# STM32F031C4T6 register map
File version: 1.0
Registers are 32-bit, access not given, reset 0x0 unless marked. A register's access mark holds for its fields unless they carry their own. Offsets are from the block's base; [hi:lo] are bit positions; {n}, {i} and the like mark numbered series.

## TIM1
Base 0x40012C00
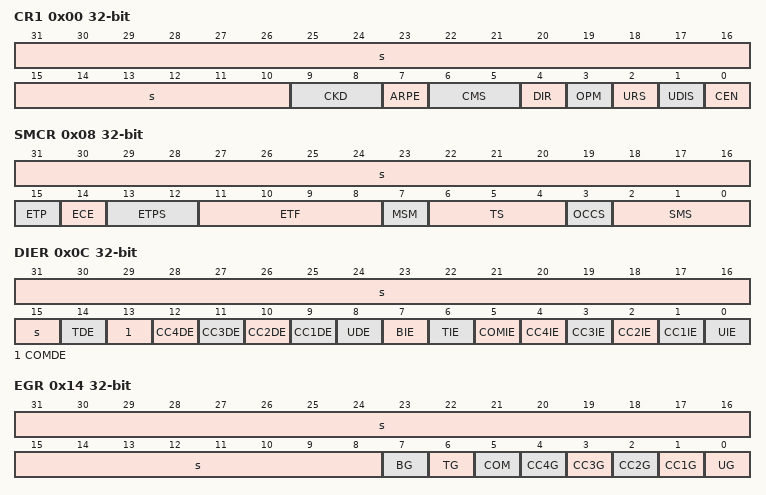
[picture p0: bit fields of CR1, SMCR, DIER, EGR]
0x00 CR1
  [31:10] s, [9:8] CKD, [7] ARPE, [6:5] CMS, [4] DIR, [3] OPM, [2] URS, [1] UDIS, [0] CEN
0x04 CR2
  [2n+6] OIS{n} (n=1..4), [13] OIS3N, [11] OIS2N, [9] OIS1N, [7] TI1S, [6:4] MMS, [3] CCDS, [2] CCUS, [31:1] s, [0] CCPC
0x08 SMCR
  [31:16] s, [15] ETP, [14] ECE, [13:12] ETPS, [11:8] ETF, [7] MSM, [6:4] TS, [3] OCCS, [2:0] SMS
0x0C DIER
  [31:15] s, [14] TDE, [13] COMDE, [n+8] CC{n}DE (n=1..4), [8] UDE, [7] BIE, [6] TIE, [5] COMIE, [n] CC{n}IE (n=1..4), [0] UIE
0x10 SR
  [n+8] CC{n}OF (n=1..4), [31:8] s, [7] BIF, [6] TIF, [5] COMIF, [n] CC{n}IF (n=1..4), [0] UIF
0x14 EGR
  [31:8] s, [7] BG, [6] TG, [5] COM, [n] CC{n}G (n=1..4), [0] UG
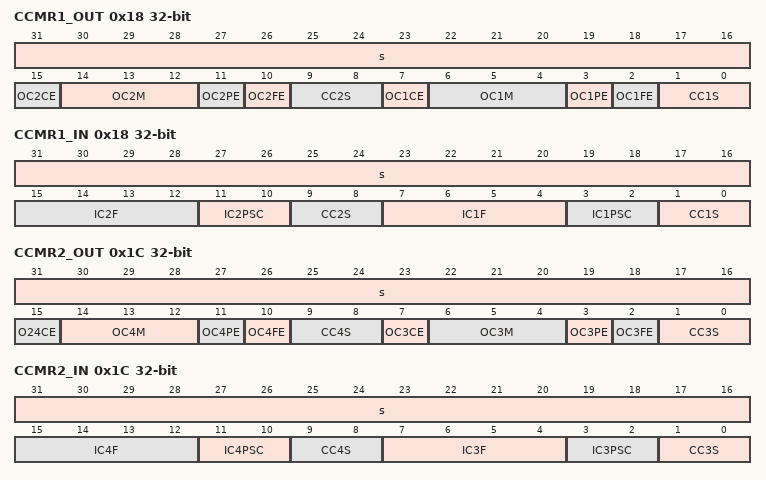
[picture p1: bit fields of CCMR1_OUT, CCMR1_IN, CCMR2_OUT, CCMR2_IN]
0x18 CCMR1_OUT
  [31:16] s, [15] OC2CE, [14:12] OC2M, [11] OC2PE, [10] OC2FE, [9:8] CC2S, [7] OC1CE, [6:4] OC1M, [3] OC1PE, [2] OC1FE, [1:0] CC1S
0x18 CCMR1_IN
  [31:16] s, [15:12] IC2F, [11:10] IC2PSC, [9:8] CC2S, [7:4] IC1F, [3:2] IC1PSC, [1:0] CC1S
0x1C CCMR2_OUT
  [31:16] s, [15] O24CE, [14:12] OC4M, [11] OC4PE, [10] OC4FE, [9:8] CC4S, [7] OC3CE, [6:4] OC3M, [3] OC3PE, [2] OC3FE, [1:0] CC3S
0x1C CCMR2_IN
  [31:16] s, [15:12] IC4F, [11:10] IC4PSC, [9:8] CC4S, [7:4] IC3F, [3:2] IC3PSC, [1:0] CC3S
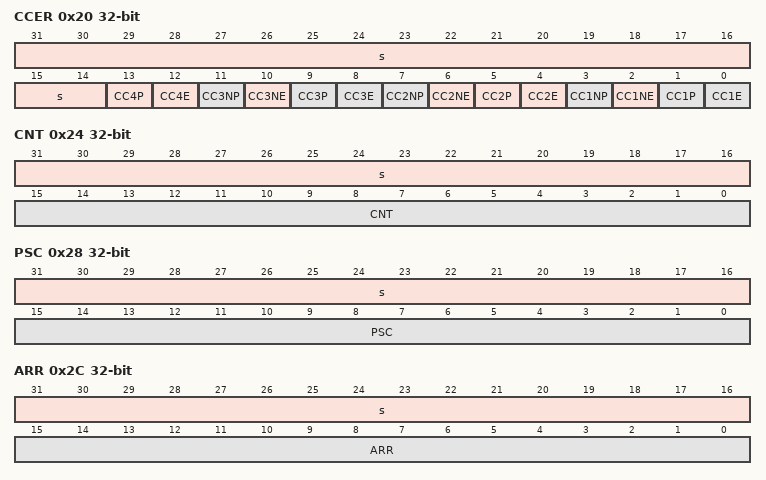
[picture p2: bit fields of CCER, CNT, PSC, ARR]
0x20 CCER
  [31:14] s, [4n-3] CC{n}P (n=1..4), [4n-4] CC{n}E (n=1..4), [11] CC3NP, [10] CC3NE, [7] CC2NP, [6] CC2NE, [3] CC1NP, [2] CC1NE
0x24 CNT
  [31:16] s, [15:0] CNT
0x28 PSC
  [31:16] s, [15:0] PSC
0x2C ARR
  [31:16] s, [15:0] ARR
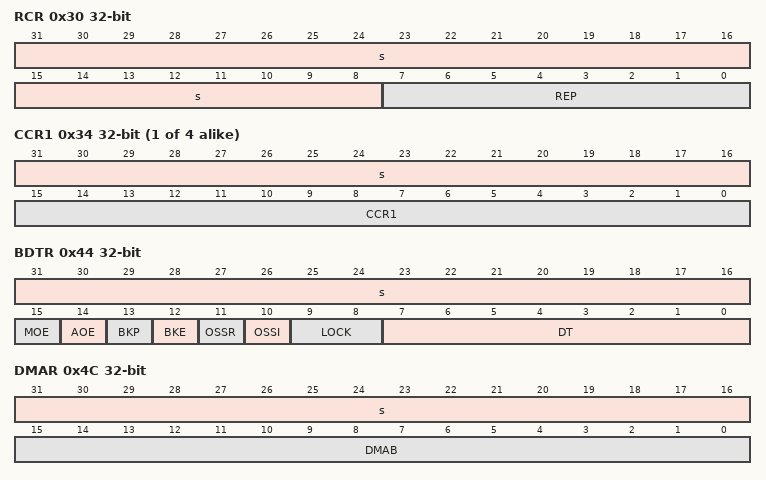
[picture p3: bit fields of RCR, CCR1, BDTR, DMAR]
0x30 RCR
  [31:8] s, [7:0] REP
{0x30+4i} CCR{i} (i=1..4)
  [31:16] s, [15:0] CCR{i}
0x44 BDTR
  [31:16] s, [15] MOE, [14] AOE, [13] BKP, [12] BKE, [11] OSSR, [10] OSSI, [9:8] LOCK, [7:0] DT
0x48 DCR
  [12:8] DBL, [31:5] s, [4:0] DBA
0x4C DMAR
  [31:16] s, [15:0] DMAB

## TIM15
Base 0x40014000
0x00 CR1
  [9:8] CKD, [7] ARPE, [31:4] s, [3] OPM, [2] URS, [1] UDIS, [0] CEN
0x04 CR2
  [10] OIS2, [9] OIS1N, [8] OIS1, [6:4] MMS, [3] CCDS, [2] CCUS, [31:1] s, [0] CCPC
0x08 SMCR
  [7] MSM, [6:4] TS, [31:3] s, [2:0] SMS
0x0C DIER
  [14] TDE, [10] CC2DE, [9] CC1DE, [8] UDE, [7] BIE, [6] TIE, [5] COMIE, [31:3] s, [2] CC2IE, [1] CC1IE, [0] UIE
0x10 SR
  [10] CC2OF, [9] CC1OF, [7] BIF, [6] TIF, [5] COMIF, [31:3] s, [2] CC2IF, [1] CC1IF, [0] UIF
0x14 EGR
  [7] BG, [6] TG, [5] COMG, [31:3] s, [2] CC2G, [1] CC1G, [0] UG
0x18 CCMR1_OUT
  [14:12] OC2M, [11] OC2PE, [10] OC2FE, [9:8] CC2S, [31:7] s, [6:4] OC1M, [3] OC1PE, [2] OC1FE, [1:0] CC1S
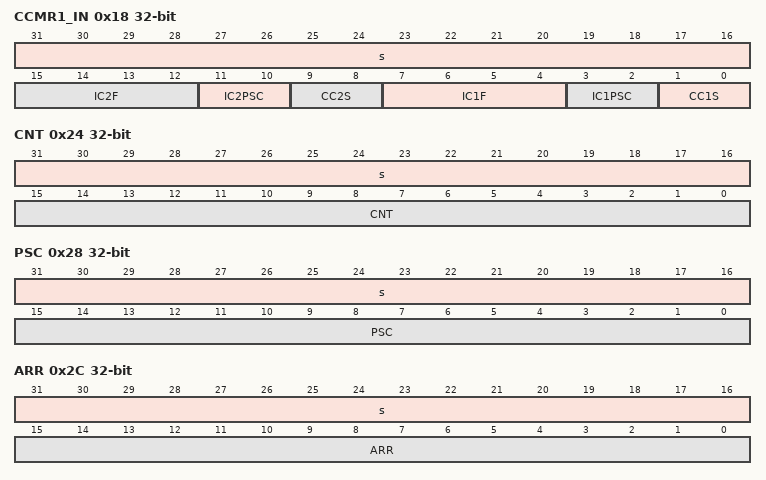
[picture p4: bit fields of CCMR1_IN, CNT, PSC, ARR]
0x18 CCMR1_IN
  [31:16] s, [15:12] IC2F, [11:10] IC2PSC, [9:8] CC2S, [7:4] IC1F, [3:2] IC1PSC, [1:0] CC1S
0x20 CCER
  [7] CC2NP, [31:6] s, [5] CC2P, [4] CC2E, [3] CC1NP, [2] CC1NE, [1] CC1P, [0] CC1E
0x24 CNT
  [31:16] s, [15:0] CNT
0x28 PSC
  [31:16] s, [15:0] PSC
0x2C ARR
  [31:16] s, [15:0] ARR
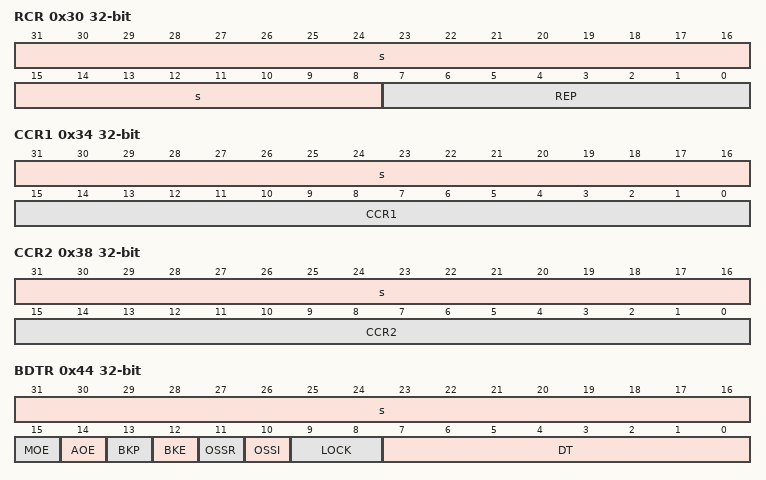
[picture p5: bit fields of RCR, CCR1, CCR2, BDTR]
0x30 RCR
  [31:8] s, [7:0] REP
0x34 CCR1
  [31:16] s, [15:0] CCR1
0x38 CCR2
  [31:16] s, [15:0] CCR2
0x44 BDTR
  [31:16] s, [15] MOE, [14] AOE, [13] BKP, [12] BKE, [11] OSSR, [10] OSSI, [9:8] LOCK, [7:0] DT
0x48 DCR
  [12:8] DBL, [31:5] s, [4:0] DBA
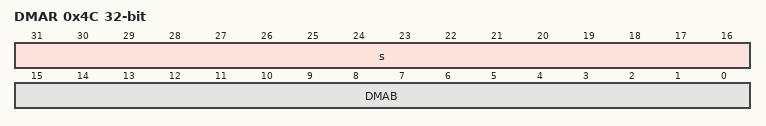
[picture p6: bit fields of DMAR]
0x4C DMAR
  [31:16] s, [15:0] DMAB

## TIM16
Base 0x40014400
Same registers: TIM17 0x40014800
Registers as TIM15, without SMCR, CCMR1_OUT, CCMR1_IN, CCR2; these are added or differ:
0x04 CR2
  [9] OIS1N, [8] OIS1, [3] CCDS, [2] CCUS, [31:1] s, [0] CCPC
0x0C DIER
  [9] CC1DE, [8] UDE, [7] BIE, [5] COMIE, [31:2] s, [1] CC1IE, [0] UIE
0x10 SR
  [9] CC1OF, [7] BIF, [5] COMIF, [31:2] s, [1] CC1IF, [0] UIF
0x14 EGR
  [7] BG, [5] COMG, [31:2] s, [1] CC1G, [0] UG
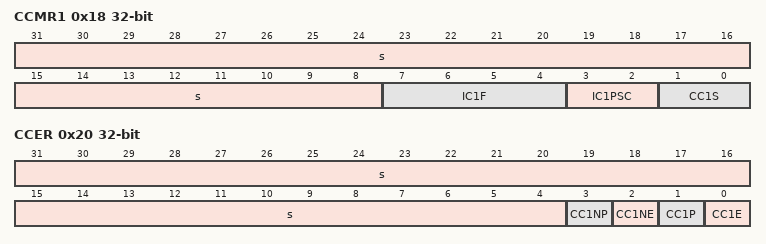
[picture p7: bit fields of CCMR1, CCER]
0x18 CCMR1
  [31:8] s, [7:4] IC1F, [3:2] IC1PSC, [1:0] CC1S
0x20 CCER
  [31:4] s, [3] CC1NP, [2] CC1NE, [1] CC1P, [0] CC1E

## DBGMCU
Base 0x40015800
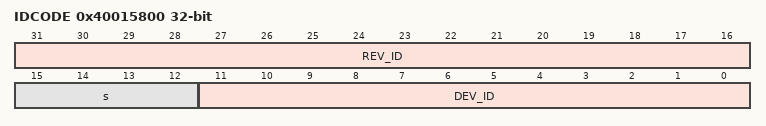
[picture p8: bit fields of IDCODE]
0x40015800 IDCODE
  [31:16] REV_ID, [15:12] s, [11:0] DEV_ID
0x40015804 CR
  [2] DBG_STANDBY, [1] DBG_STOP, [31:0] s
0x40015808 APB1_FZ
  [25] DBG_CAN_STOP, [21] DBG_I2C1_SMBUS_TIMEOUT, [12] DBG_IWDG_STOP, [11] DBG_WWDG_STOP, [10] DBG_RTC_STOP, [8] DBG_TIM14_STOP, [5] DBG_TIM7_STOP, [4] DBG_TIM6_STOP, [31:2] s, [1] DBG_TIM3_STOP, [0] DBG_TIM2_STOP
0x4001580C APB2_FZ
  [18] DBG_TIM17_STOP, [17] DBG_TIM16_STOP, [16] DBG_TIM15_STOP, [11] DBG_TIM1_STOP, [31:0] s
